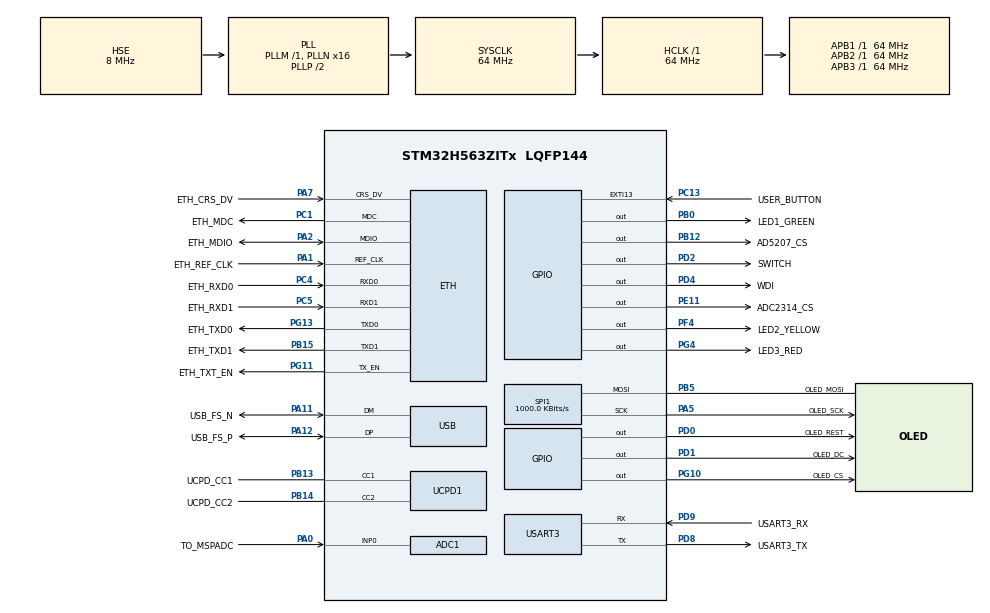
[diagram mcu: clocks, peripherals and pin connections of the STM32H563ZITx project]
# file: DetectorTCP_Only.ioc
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ADC1.Channel-0\#ChannelRegularConversion=ADC_CHANNEL_0
ADC1.ClockPrescaler=ADC_CLOCK_ASYNC_DIV2
ADC1.ContinuousConvMode=DISABLE
ADC1.DMAContinuousRequests=DISABLE
ADC1.DataAlign=ADC_DATAALIGN_RIGHT
ADC1.EOCSelection=ADC_EOC_SINGLE_CONV
ADC1.EnableRegularConversion=ENABLE
ADC1.LowPowerAutoWait=DISABLE
ADC1.MonitoredBy-0\#ChannelRegularConversion=__NULL
ADC1.NbrOfConversionFlag=1
ADC1.OffsetNumber-0\#ChannelRegularConversion=ADC_OFFSET_NONE
ADC1.Overrun=ADC_OVR_DATA_PRESERVED
ADC1.OversamplingMode=DISABLE
ADC1.Rank-0\#ChannelRegularConversion=1
ADC1.Resolution=ADC_RESOLUTION_12B
ADC1.SamplingTime-0\#ChannelRegularConversion=ADC_SAMPLETIME_2CYCLES_5
ADC1.master=1
BOOTPATH.BootPathName=LEGACY
BOOTPATH.UserSelectedBootPath=LEGACY
CORTEX_M33_NS.userName=CORTEX_M33
ETH.MediaInterface=HAL_ETH_RMII_MODE
FLASH.OB_EDATA1_active=true
FLASH.OB_EDATA2_active=true
GPDMA1.DIRECTION_GPDMACH0=DMA_MEMORY_TO_PERIPH
GPDMA1.IPHANDLE_GPDMACH0-SIMPLEREQUEST_GPDMACH0=__NULL
GPDMA1.RECAP_GPDMACH0=DMA_REQUEST_USART3_TX
GPDMA1.REQUEST_GPDMACH0=GPDMA1_REQUEST_USART3_RX
GPDMA1.SRCINC_GPDMACH0=DMA_SINC_INCREMENTED
GPDMA2.CIRCULARMODE_GPDMACH0=ENABLE
GPDMA2.DESTDATAWIDTH_GPDMACH0=DMA_DEST_DATAWIDTH_HALFWORD
GPDMA2.DESTINC_GPDMACH0=DMA_DINC_INCREMENTED
GPDMA2.DIRECTION_GPDMACH0=DMA_PERIPH_TO_MEMORY
GPDMA2.IPHANDLE_GPDMACH0-SIMPLEREQUEST_GPDMACH0=__NULL
GPDMA2.LINKALLOCATEDPORT_CIRCULAR_GPDMACH0=DMA_LINK_ALLOCATED_PORT1
GPDMA2.PRIORITY_LL_CIRCULAR_GPDMACH0=DMA_LOW_PRIORITY_HIGH_WEIGHT
GPDMA2.RECAP_GPDMACH0=DMA_REQUEST_ADC1
GPDMA2.REQUEST_GPDMACH0=GPDMA2_REQUEST_ADC1
GPDMA2.SRCDATAWIDTH_GPDMACH0=DMA_SRC_DATAWIDTH_HALFWORD
GPDMA2.TRANSFERALLOCATEDPORTDEST_GPDMACH0=DMA_DEST_ALLOCATED_PORT1
GPDMA2.TRANSFERALLOCATEDPORTSRC_GPDMACH0=DMA_SRC_ALLOCATED_PORT1
Mcu.Family=STM32H5
Mcu.Name=STM32H563ZITx
Mcu.Package=LQFP144
NETXDUO.ETH_ON=1
NETXDUO.LAN_8742=1
NETXDUO.NX_APP_MEM_POOL_SIZE=30*1024
NETXDUO.NX_APP_PACKET_POOL_SIZE=10
NETXDUO.NX_APP_THREAD_STACK_SIZE=2*1024
NETXDUO.NX_ENABLE_DUAL_PACKET_POOL=true
NETXDUO.NX_ENABLE_INTERFACE_CAPABILITY=true
NETXDUO.NetXDuo_Generate_Init_Code=true
NVIC.ETH_IRQn=true\:0\:0\:false\:false\:true\:false\:true\:true\:true
NVIC.GPDMA1_Channel0_IRQn=true\:0\:0\:false\:false\:true\:false\:false\:true\:true
NVIC.GPDMA2_Channel0_IRQn=true\:0\:0\:false\:false\:true\:true\:false\:true\:true
NVIC.PriorityGroup=NVIC_PRIORITYGROUP_4
NVIC.TIM6_IRQn=true\:15\:0\:false\:false\:true\:false\:false\:true\:true
NVIC.TimeBase=TIM6_IRQn
NVIC.TimeBaseIP=TIM6
NVIC.USART3_IRQn=true\:0\:0\:false\:false\:true\:false\:true\:true\:true
NetXDuo.BSP.number=1
NetXDuo0.BSP.STBoard=false
NetXDuo0.BSP.api=BSP_COMPONENT_DRIVER
NetXDuo0.BSP.component=lan8742
NetXDuo0.BSP.instance=lan8742
NetXDuo0.BSP.name=LAN_Component
NetXDuo0.BSP.semaphore=SEMA_lan8742
NetXDuo0.BSP.solution=lan8742
PA0.GPIO_Label=TO_MSPADC
PA0.Signal=ADCx_INP0
PA1.GPIO_Label=ETH_REF_CLK
PA1.GPIO_Mode=GPIO_MODE_AF_PP
PA1.GPIO_PuPd=GPIO_NOPULL
PA1.GPIO_Speed=GPIO_SPEED_FREQ_LOW
PA1.Mode=RMII
PA1.Signal=ETH_REF_CLK
PA11.GPIO_Label=USB_FS_N
PA11.Mode=Device
PA11.Signal=USB_DM
PA12.GPIO_Label=USB_FS_P
PA12.Mode=Device
PA12.Signal=USB_DP
PA2.GPIO_Label=ETH_MDIO
PA2.GPIO_Mode=GPIO_MODE_AF_PP
PA2.GPIO_PuPd=GPIO_NOPULL
PA2.GPIO_Speed=GPIO_SPEED_FREQ_LOW
PA2.Mode=RMII
PA2.Signal=ETH_MDIO
PA5.GPIO_Label=OLED_SCK
PA5.GPIO_Mode=GPIO_MODE_AF_PP
PA5.GPIO_PuPd=GPIO_NOPULL
PA5.GPIO_Speed=GPIO_SPEED_FREQ_LOW
PA5.Mode=Simplex_Bidirectional_Master
PA5.Signal=SPI1_SCK
PA7.GPIO_Label=ETH_CRS_DV
PA7.GPIO_Mode=GPIO_MODE_AF_PP
PA7.GPIO_PuPd=GPIO_NOPULL
PA7.GPIO_Speed=GPIO_SPEED_FREQ_LOW
PA7.Mode=RMII
PA7.Signal=ETH_CRS_DV
PB0.GPIO_Label=LED1_GREEN
PB0.Signal=GPIO_Output
PB10.GPIO_Label=ADC_CLCK
PB10.Signal=SPI2_SCK
PB12.GPIO_Label=AD5207_CS
PB12.Signal=GPIO_Output
PB13.GPIO_Label=UCPD_CC1
PB13.Mode=Source_AllSignals
PB13.Signal=UCPD1_CC1
PB14.GPIO_Label=UCPD_CC2
PB14.Mode=Source_AllSignals
PB14.Signal=UCPD1_CC2
PB15.GPIO_Label=ETH_TXD1
PB15.GPIO_Mode=GPIO_MODE_AF_PP
PB15.GPIO_PuPd=GPIO_NOPULL
PB15.GPIO_Speed=GPIO_SPEED_FREQ_LOW
PB15.Mode=RMII
PB15.Signal=ETH_TXD1
PB5.GPIO_Label=OLED_MOSI
PB5.GPIO_Mode=GPIO_MODE_AF_PP
PB5.GPIO_PuPd=GPIO_NOPULL
PB5.GPIO_Speed=GPIO_SPEED_FREQ_LOW
PB5.Mode=Simplex_Bidirectional_Master
PB5.Signal=SPI1_MOSI
PC1.GPIO_Label=ETH_MDC
PC1.GPIO_Mode=GPIO_MODE_AF_PP
PC1.GPIO_PuPd=GPIO_NOPULL
PC1.GPIO_Speed=GPIO_SPEED_FREQ_LOW
PC1.Mode=RMII
PC1.Signal=ETH_MDC
PC13.GPIO_Label=USER_BUTTON
PC13.Signal=GPXTI13
PC3.GPIO_Label=AD5207_SDI
PC3.Signal=SPI2_MOSI
PC4.GPIO_Label=ETH_RXD0
PC4.GPIO_Mode=GPIO_MODE_AF_PP
PC4.GPIO_PuPd=GPIO_NOPULL
PC4.GPIO_Speed=GPIO_SPEED_FREQ_LOW
PC4.Mode=RMII
PC4.Signal=ETH_RXD0
PC5.GPIO_Label=ETH_RXD1
PC5.GPIO_Mode=GPIO_MODE_AF_PP
PC5.GPIO_PuPd=GPIO_NOPULL
PC5.GPIO_Speed=GPIO_SPEED_FREQ_LOW
PC5.Mode=RMII
PC5.Signal=ETH_RXD1
PD0.GPIO_Label=OLED_REST
PD0.GPIO_PuPd=GPIO_NOPULL
PD0.PinState=GPIO_PIN_SET
PD0.Signal=GPIO_Output
PD1.GPIO_Label=OLED_DC
PD1.Signal=GPIO_Output
PD2.GPIO_Label=SWITCH
PD2.Signal=GPIO_Output
PD4.GPIO_Label=WDI
PD4.Signal=GPIO_Output
PD8.GPIO_Label=USART3_TX
PD8.Mode=Asynchronous
PD8.Signal=USART3_TX
PD9.GPIO_Label=USART3_RX
PD9.Mode=Asynchronous
PD9.Signal=USART3_RX
PE11.GPIO_Label=ADC2314_CS
PE11.Signal=GPIO_Output
PE12.GPIO_Label=ADC2314_SCK
PE12.Signal=SPI4_SCK
PE13.GPIO_Label=ADC2314_MISO
PE13.Signal=SPI4_MISO
PF4.GPIO_Label=LED2_YELLOW
PF4.Signal=GPIO_Output
PG10.GPIO_Label=OLED_CS
PG10.Signal=GPIO_Output
PG11.GPIO_Label=ETH_TXT_EN
PG11.GPIO_Mode=GPIO_MODE_AF_PP
PG11.GPIO_PuPd=GPIO_NOPULL
PG11.GPIO_Speed=GPIO_SPEED_FREQ_LOW
PG11.Mode=RMII
PG11.Signal=ETH_TX_EN
PG13.GPIO_Label=ETH_TXD0
PG13.GPIO_Mode=GPIO_MODE_AF_PP
PG13.GPIO_PuPd=GPIO_NOPULL
PG13.GPIO_Speed=GPIO_SPEED_FREQ_LOW
PG13.Mode=RMII
PG13.Signal=ETH_TXD0
PG4.GPIO_Label=LED3_RED
PG4.Signal=GPIO_Output
PH0-OSC_IN(PH0).Mode=HSE-External-Clock-Source
PH0-OSC_IN(PH0).Signal=RCC_OSC_IN
ProjectManager.HeapSize=0x200
ProjectManager.StackSize=0x400
ProjectManager.TargetToolchain=STM32CubeIDE
RCC.ADCFreq_Value=64000000
RCC.AHBFreq_Value=64000000
RCC.APB1Freq_Value=64000000
RCC.APB1TimFreq_Value=64000000
RCC.APB2Freq_Value=64000000
RCC.APB2TimFreq_Value=64000000
RCC.APB3Freq_Value=64000000
RCC.CSI_VALUE=4000000
RCC.CortexFreq_Value=64000000
RCC.EPOD_VALUE=8000000
RCC.HCLKFreq_Value=64000000
RCC.HSE_VALUE=8000000
RCC.HSI48_VALUE=48000000
RCC.HSIDiv=RCC_HSI_DIV1
RCC.HSI_VALUE=64000000
RCC.LSE_VALUE=32768
RCC.LSIRC_VALUE=32000
RCC.PLL2FRACN=0
RCC.PLL3FRACN=0
RCC.PLLFRACN=0
RCC.PLLN=16
RCC.PLLSourceVirtual=RCC_PLL1_SOURCE_HSE
RCC.PWR_Regulator_Voltage_Scale=PWR_REGULATOR_VOLTAGE_SCALE0
RCC.SYSCLKFreq_VALUE=64000000
RCC.SYSCLKSource=RCC_SYSCLKSOURCE_PLLCLK
RCC.USBFreq_Value=48000000
RCC.VCOOutputFreq_Value=128000000
RCC.rccPrivilegeNSecure=RCC_NSEC_PRIV
SH.ADCx_INP0.0=ADC1_INP0,IN0-Single-Ended
SPI1.BaudRatePrescaler=SPI_BAUDRATEPRESCALER_64
SPI1.CLKPolarity=SPI_POLARITY_LOW
SPI1.CalculateBaudRate=1000.0 KBits/s
SPI1.DataSize=SPI_DATASIZE_8BIT
SPI1.Direction=SPI_DIRECTION_1LINE
SPI1.IOSwap=SPI_IO_SWAP_DISABLE
SPI1.MasterInterDataIdleness=SPI_MASTER_INTERDATA_IDLENESS_00CYCLE
SPI1.MasterKeepIOState=SPI_MASTER_KEEP_IO_STATE_ENABLE
SPI1.MasterReceiverAutoSusp=SPI_MASTER_RX_AUTOSUSP_ENABLE
SPI1.MasterSSIdleness=SPI_MASTER_SS_IDLENESS_00CYCLE
SPI1.Mode=SPI_MODE_MASTER
SPI1.NSSPolarity=SPI_NSS_POLARITY_HIGH
SPI1.ReadyPolarity=SPI_RDY_POLARITY_LOW
SPI1.VirtualType=VM_MASTER
TIM13.AutoReloadPreload=TIM_AUTORELOAD_PRELOAD_ENABLE
TIM13.ClockDivision=TIM_CLOCKDIVISION_DIV2
TIM13.PeriodNoDither=525
USART3.DataInvertParam=ADVFEATURE_DATAINV_DISABLE
USART3.MSBFirstParam=ADVFEATURE_MSBFIRST_DISABLE
USART3.OverSampling=UART_OVERSAMPLING_16
USART3.RxPinLevelInvertParam=ADVFEATURE_RXINV_DISABLE
USART3.VirtualMode=VM_ASYNC
USART3.WordLength=WORDLENGTH_8B
USB.VirtualMode=Device_Only
VP_BOOTPATH_VS_BOOTPATH.Mode=BP_Activate
VP_FLASH_SIG_Activate_FlashIP.Mode=Activate_FlashIP
VP_GPDMA1_VS_GPDMACH0.Mode=SIMPLEREQUEST_GPDMACH0
VP_GPDMA2_VS_GPDMACH0.Mode=SIMPLEREQUEST_GPDMACH0
VP_ICACHE_VS_ICACHE.Mode=DefaultMode
VP_MEMORYMAP_VS_MEMORYMAP.Mode=CurAppReg
VP_NETXDUO_VS_AddonsOoDHCP.Mode=Addons_DHCP_Client
VP_NETXDUO_VS_EthernetOoPhyOoInterface.Mode=LAN8742_Phy_Interface
VP_NETXDUO_VS_NXOoCore.Mode=NX_Core
VP_NETXDUO_VS_NetworkOoInterface.Mode=Ethernet_Interface
VP_PWR_VS_DBSignals.Mode=DisableDeadBatterySignals
VP_PWR_VS_LPOM.Mode=PowerOptimisation
VP_PWR_VS_SECSignals.Mode=Security/Privilege
VP_SYS_VS_tim6.Mode=TIM6
VP_THREADX_VS_RTOSJjThreadXJjCoreJjDefault.Mode=Core_Default
VP_TIM13_VS_ClockSourceINT.Mode=Enable_Timer
board=NUCLEO-H563ZI

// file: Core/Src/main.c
/* USER CODE BEGIN Header */
/**
  ******************************************************************************
  * @file           : main.c
  * @brief          : Main program body
  ******************************************************************************
  * @attention
  *
  * Copyright (c) 2024 STMicroelectronics.
  * All rights reserved.
  *
  * This software is licensed under terms that can be found in the LICENSE file
  * in the root directory of this software component.
  * If no LICENSE file comes with this software, it is provided AS-IS.
  *
  ******************************************************************************
  */
/* USER CODE END Header */
#include "app_threadx.h"
#include "main.h"
#include "string.h"

/* USER CODE BEGIN Includes */
#include <stdio.h>
#include "../vs_info.h"
#include "../global.h"
#include "../hal_src/HAL.h"
#include "../ssd1306_src/ssd1306.h"
#include "../ssd1306_src/ssd1306_tests.h"
#include "../ssd1306_src/ssd1306_conf.h"
/* USER CODE END Includes */

ETH_TxPacketConfig TxConfig;
ETH_DMADescTypeDef  DMARxDscrTab[ETH_RX_DESC_CNT]; /* Ethernet Rx DMA Descriptors */
ETH_DMADescTypeDef  DMATxDscrTab[ETH_TX_DESC_CNT]; /* Ethernet Tx DMA Descriptors */

ADC_HandleTypeDef hadc1;
DMA_NodeTypeDef Node_GPDMA2_Channel0;
DMA_QListTypeDef List_GPDMA2_Channel0;
DMA_HandleTypeDef handle_GPDMA2_Channel0;

ETH_HandleTypeDef heth;

SPI_HandleTypeDef hspi1;

TIM_HandleTypeDef htim13;

UART_HandleTypeDef huart3;
DMA_HandleTypeDef handle_GPDMA1_Channel0;

PCD_HandleTypeDef hpcd_USB_DRD_FS;

void SystemClock_Config(void);
static void MX_GPIO_Init(void);
static void MX_GPDMA1_Init(void);
static void MX_GPDMA2_Init(void);
static void MX_ICACHE_Init(void);
static void MX_USART3_UART_Init(void);
static void MX_UCPD1_Init(void);
static void MX_USB_PCD_Init(void);
static void MX_ADC1_Init(void);
static void MX_SPI1_Init(void);
static void MX_ETH_Init(void);
static void MX_TIM13_Init(void);
static void MX_FLASH_Init(void);

int main(void)
{

  /* MCU Configuration--------------------------------------------------------*/

  /* Reset of all peripherals, Initializes the Flash interface and the Systick. */
  HAL_Init();

  /* Configure the system clock */
  SystemClock_Config();

  /* Initialize all configured peripherals */
  MX_GPIO_Init();
  MX_GPDMA1_Init();
  MX_GPDMA2_Init();
  MX_ICACHE_Init();
  MX_USART3_UART_Init();
  MX_UCPD1_Init();
  MX_USB_PCD_Init();
  MX_ADC1_Init();
  MX_SPI1_Init();
  MX_ETH_Init();
  MX_TIM13_Init();
  MX_FLASH_Init();
  /* USER CODE BEGIN 2 */
  Output("Patates!$");
  /* USER CODE END 2 */

  MX_ThreadX_Init();

  /* We should never get here as control is now taken by the scheduler */
  /* Infinite loop */
  while (1)
  {

  }
}

void SystemClock_Config(void)
{
  RCC_OscInitTypeDef RCC_OscInitStruct = {0};
  RCC_ClkInitTypeDef RCC_ClkInitStruct = {0};

  /** Configure the main internal regulator output voltage
  */
  __HAL_PWR_VOLTAGESCALING_CONFIG(PWR_REGULATOR_VOLTAGE_SCALE0);

  while(!__HAL_PWR_GET_FLAG(PWR_FLAG_VOSRDY)) {}

  /** Initializes the RCC Oscillators according to the specified parameters
  * in the RCC_OscInitTypeDef structure.
  */
  RCC_OscInitStruct.OscillatorType = RCC_OSCILLATORTYPE_HSI48|RCC_OSCILLATORTYPE_HSI
                              |RCC_OSCILLATORTYPE_HSE;
  RCC_OscInitStruct.HSEState = RCC_HSE_BYPASS;
  RCC_OscInitStruct.HSIState = RCC_HSI_ON;
  RCC_OscInitStruct.HSIDiv = RCC_HSI_DIV1;
  RCC_OscInitStruct.HSICalibrationValue = RCC_HSICALIBRATION_DEFAULT;
  RCC_OscInitStruct.HSI48State = RCC_HSI48_ON;
  RCC_OscInitStruct.PLL.PLLState = RCC_PLL_ON;
  RCC_OscInitStruct.PLL.PLLSource = RCC_PLL1_SOURCE_HSE;
  RCC_OscInitStruct.PLL.PLLM = 1;
  RCC_OscInitStruct.PLL.PLLN = 16;
  RCC_OscInitStruct.PLL.PLLP = 2;
  RCC_OscInitStruct.PLL.PLLQ = 2;
  RCC_OscInitStruct.PLL.PLLR = 2;
  RCC_OscInitStruct.PLL.PLLRGE = RCC_PLL1_VCIRANGE_3;
  RCC_OscInitStruct.PLL.PLLVCOSEL = RCC_PLL1_VCORANGE_WIDE;
  RCC_OscInitStruct.PLL.PLLFRACN = 0;
  if (HAL_RCC_OscConfig(&RCC_OscInitStruct) != HAL_OK)
  {
    Error_Handler();
  }

  /** Initializes the CPU, AHB and APB buses clocks
  */
  RCC_ClkInitStruct.ClockType = RCC_CLOCKTYPE_HCLK|RCC_CLOCKTYPE_SYSCLK
                              |RCC_CLOCKTYPE_PCLK1|RCC_CLOCKTYPE_PCLK2
                              |RCC_CLOCKTYPE_PCLK3;
  RCC_ClkInitStruct.SYSCLKSource = RCC_SYSCLKSOURCE_PLLCLK;
  RCC_ClkInitStruct.AHBCLKDivider = RCC_SYSCLK_DIV1;
  RCC_ClkInitStruct.APB1CLKDivider = RCC_HCLK_DIV1;
  RCC_ClkInitStruct.APB2CLKDivider = RCC_HCLK_DIV1;
  RCC_ClkInitStruct.APB3CLKDivider = RCC_HCLK_DIV1;

  if (HAL_RCC_ClockConfig(&RCC_ClkInitStruct, FLASH_LATENCY_1) != HAL_OK)
  {
    Error_Handler();
  }
  HAL_RCC_ConfigAttributes(RCC_ALL, RCC_NSEC_PRIV);
}

static void MX_ADC1_Init(void)
{

  ADC_ChannelConfTypeDef sConfig = {0};

  /** Common config
  */
  hadc1.Instance = ADC1;
  hadc1.Init.ClockPrescaler = ADC_CLOCK_ASYNC_DIV2;
  hadc1.Init.Resolution = ADC_RESOLUTION_12B;
  hadc1.Init.DataAlign = ADC_DATAALIGN_RIGHT;
  hadc1.Init.ScanConvMode = ADC_SCAN_DISABLE;
  hadc1.Init.EOCSelection = ADC_EOC_SINGLE_CONV;
  hadc1.Init.LowPowerAutoWait = DISABLE;
  hadc1.Init.ContinuousConvMode = DISABLE;
  hadc1.Init.NbrOfConversion = 1;
  hadc1.Init.DiscontinuousConvMode = DISABLE;
  hadc1.Init.ExternalTrigConv = ADC_SOFTWARE_START;
  hadc1.Init.ExternalTrigConvEdge = ADC_EXTERNALTRIGCONVEDGE_NONE;
  hadc1.Init.DMAContinuousRequests = DISABLE;
  hadc1.Init.SamplingMode = ADC_SAMPLING_MODE_NORMAL;
  hadc1.Init.Overrun = ADC_OVR_DATA_PRESERVED;
  hadc1.Init.OversamplingMode = DISABLE;
  if (HAL_ADC_Init(&hadc1) != HAL_OK)
  {
    Error_Handler();
  }

  /** Configure Regular Channel
  */
  sConfig.Channel = ADC_CHANNEL_0;
  sConfig.Rank = ADC_REGULAR_RANK_1;
  sConfig.SamplingTime = ADC_SAMPLETIME_2CYCLES_5;
  sConfig.SingleDiff = ADC_SINGLE_ENDED;
  sConfig.OffsetNumber = ADC_OFFSET_NONE;
  sConfig.Offset = 0;
  if (HAL_ADC_ConfigChannel(&hadc1, &sConfig) != HAL_OK)
  {
    Error_Handler();
  }

}

static void MX_ETH_Init(void)
{

   static uint8_t MACAddr[6];

  heth.Instance = ETH;
  MACAddr[0] = 0x00;
  MACAddr[1] = 0x80;
  MACAddr[2] = 0xE1;
  MACAddr[3] = 0x00;
  MACAddr[4] = 0x00;
  MACAddr[5] = 0x00;
  heth.Init.MACAddr = &MACAddr[0];
  heth.Init.MediaInterface = HAL_ETH_RMII_MODE;
  heth.Init.TxDesc = DMATxDscrTab;
  heth.Init.RxDesc = DMARxDscrTab;
  heth.Init.RxBuffLen = 1524;

  if (HAL_ETH_Init(&heth) != HAL_OK)
  {
    Error_Handler();
  }

  memset(&TxConfig, 0 , sizeof(ETH_TxPacketConfig));
  TxConfig.Attributes = ETH_TX_PACKETS_FEATURES_CSUM | ETH_TX_PACKETS_FEATURES_CRCPAD;
  TxConfig.ChecksumCtrl = ETH_CHECKSUM_IPHDR_PAYLOAD_INSERT_PHDR_CALC;
  TxConfig.CRCPadCtrl = ETH_CRC_PAD_INSERT;

}

static void MX_FLASH_Init(void)
{

  FLASH_OBProgramInitTypeDef pOBInit = {0};

  if (HAL_FLASH_Unlock() != HAL_OK)
  {
    Error_Handler();
  }

  /* Option Bytes settings */

  if (HAL_FLASH_OB_Unlock() != HAL_OK)
  {
    Error_Handler();
  }
  pOBInit.OptionType = OPTIONBYTE_EDATA;
  pOBInit.Banks = FLASH_BANK_BOTH;
  pOBInit.EDATASize = 0;
  if (HAL_FLASHEx_OBProgram(&pOBInit) != HAL_OK)
  {
    Error_Handler();
  }
  if (HAL_FLASH_OB_Lock() != HAL_OK)
  {
    Error_Handler();
  }
  if (HAL_FLASH_Lock() != HAL_OK)
  {
    Error_Handler();
  }

  /* Launch Option Bytes Loading */
  /*HAL_FLASH_OB_Launch(); */

}

static void MX_GPDMA1_Init(void)
{

  /* Peripheral clock enable */
  __HAL_RCC_GPDMA1_CLK_ENABLE();

  /* GPDMA1 interrupt Init */
    HAL_NVIC_SetPriority(GPDMA1_Channel0_IRQn, 0, 0);
    HAL_NVIC_EnableIRQ(GPDMA1_Channel0_IRQn);

}

static void MX_GPDMA2_Init(void)
{

  /* Peripheral clock enable */
  __HAL_RCC_GPDMA2_CLK_ENABLE();

  /* GPDMA2 interrupt Init */
    HAL_NVIC_SetPriority(GPDMA2_Channel0_IRQn, 0, 0);
    HAL_NVIC_EnableIRQ(GPDMA2_Channel0_IRQn);

}

static void MX_ICACHE_Init(void)
{

  /** Enable instruction cache (default 2-ways set associative cache)
  */
  if (HAL_ICACHE_Enable() != HAL_OK)
  {
    Error_Handler();
  }

}

static void MX_SPI1_Init(void)
{

  /* SPI1 parameter configuration*/
  hspi1.Instance = SPI1;
  hspi1.Init.Mode = SPI_MODE_MASTER;
  hspi1.Init.Direction = SPI_DIRECTION_1LINE;
  hspi1.Init.DataSize = SPI_DATASIZE_8BIT;
  hspi1.Init.CLKPolarity = SPI_POLARITY_LOW;
  hspi1.Init.CLKPhase = SPI_PHASE_1EDGE;
  hspi1.Init.NSS = SPI_NSS_SOFT;
  hspi1.Init.BaudRatePrescaler = SPI_BAUDRATEPRESCALER_64;
  hspi1.Init.FirstBit = SPI_FIRSTBIT_MSB;
  hspi1.Init.TIMode = SPI_TIMODE_DISABLE;
  hspi1.Init.CRCCalculation = SPI_CRCCALCULATION_DISABLE;
  hspi1.Init.CRCPolynomial = 0x7;
  hspi1.Init.NSSPMode = SPI_NSS_PULSE_ENABLE;
  hspi1.Init.NSSPolarity = SPI_NSS_POLARITY_HIGH;
  hspi1.Init.FifoThreshold = SPI_FIFO_THRESHOLD_01DATA;
  hspi1.Init.MasterSSIdleness = SPI_MASTER_SS_IDLENESS_00CYCLE;
  hspi1.Init.MasterInterDataIdleness = SPI_MASTER_INTERDATA_IDLENESS_00CYCLE;
  hspi1.Init.MasterReceiverAutoSusp = SPI_MASTER_RX_AUTOSUSP_ENABLE;
  hspi1.Init.MasterKeepIOState = SPI_MASTER_KEEP_IO_STATE_ENABLE;
  hspi1.Init.IOSwap = SPI_IO_SWAP_DISABLE;
  hspi1.Init.ReadyMasterManagement = SPI_RDY_MASTER_MANAGEMENT_INTERNALLY;
  hspi1.Init.ReadyPolarity = SPI_RDY_POLARITY_LOW;
  if (HAL_SPI_Init(&hspi1) != HAL_OK)
  {
    Error_Handler();
  }

}

static void MX_TIM13_Init(void)
{

  htim13.Instance = TIM13;
  htim13.Init.Prescaler = 0;
  htim13.Init.CounterMode = TIM_COUNTERMODE_UP;
  htim13.Init.Period = 525;
  htim13.Init.ClockDivision = TIM_CLOCKDIVISION_DIV2;
  htim13.Init.AutoReloadPreload = TIM_AUTORELOAD_PRELOAD_ENABLE;
  if (HAL_TIM_Base_Init(&htim13) != HAL_OK)
  {
    Error_Handler();
  }

}

static void MX_UCPD1_Init(void)
{

  LL_GPIO_InitTypeDef GPIO_InitStruct = {0};

  /* Peripheral clock enable */
  LL_APB1_GRP2_EnableClock(LL_APB1_GRP2_PERIPH_UCPD1);

  LL_AHB2_GRP1_EnableClock(LL_AHB2_GRP1_PERIPH_GPIOB);
  /**UCPD1 GPIO Configuration
  PB13   ------> UCPD1_CC1
  PB14   ------> UCPD1_CC2
  */
  GPIO_InitStruct.Pin = LL_GPIO_PIN_13|LL_GPIO_PIN_14;
  GPIO_InitStruct.Mode = LL_GPIO_MODE_ANALOG;
  GPIO_InitStruct.Pull = LL_GPIO_PULL_NO;
  LL_GPIO_Init(GPIOB, &GPIO_InitStruct);

}

static void MX_USART3_UART_Init(void)
{

  huart3.Instance = USART3;
  huart3.Init.BaudRate = 115200;
  huart3.Init.WordLength = UART_WORDLENGTH_8B;
  huart3.Init.StopBits = UART_STOPBITS_1;
  huart3.Init.Parity = UART_PARITY_NONE;
  huart3.Init.Mode = UART_MODE_TX_RX;
  huart3.Init.HwFlowCtl = UART_HWCONTROL_NONE;
  huart3.Init.OverSampling = UART_OVERSAMPLING_16;
  huart3.Init.OneBitSampling = UART_ONE_BIT_SAMPLE_DISABLE;
  huart3.Init.ClockPrescaler = UART_PRESCALER_DIV1;
  huart3.AdvancedInit.AdvFeatureInit = UART_ADVFEATURE_NO_INIT;
  if (HAL_UART_Init(&huart3) != HAL_OK)
  {
    Error_Handler();
  }
  if (HAL_UARTEx_SetTxFifoThreshold(&huart3, UART_TXFIFO_THRESHOLD_1_8) != HAL_OK)
  {
    Error_Handler();
  }
  if (HAL_UARTEx_SetRxFifoThreshold(&huart3, UART_RXFIFO_THRESHOLD_1_8) != HAL_OK)
  {
    Error_Handler();
  }
  if (HAL_UARTEx_DisableFifoMode(&huart3) != HAL_OK)
  {
    Error_Handler();
  }

}

static void MX_USB_PCD_Init(void)
{

  hpcd_USB_DRD_FS.Instance = USB_DRD_FS;
  hpcd_USB_DRD_FS.Init.dev_endpoints = 8;
  hpcd_USB_DRD_FS.Init.speed = USBD_FS_SPEED;
  hpcd_USB_DRD_FS.Init.phy_itface = PCD_PHY_EMBEDDED;
  hpcd_USB_DRD_FS.Init.Sof_enable = DISABLE;
  hpcd_USB_DRD_FS.Init.low_power_enable = DISABLE;
  hpcd_USB_DRD_FS.Init.lpm_enable = DISABLE;
  hpcd_USB_DRD_FS.Init.battery_charging_enable = DISABLE;
  hpcd_USB_DRD_FS.Init.vbus_sensing_enable = DISABLE;
  hpcd_USB_DRD_FS.Init.bulk_doublebuffer_enable = DISABLE;
  hpcd_USB_DRD_FS.Init.iso_singlebuffer_enable = DISABLE;
  if (HAL_PCD_Init(&hpcd_USB_DRD_FS) != HAL_OK)
  {
    Error_Handler();
  }

}

static void MX_GPIO_Init(void)
{
  GPIO_InitTypeDef GPIO_InitStruct = {0};

  /* GPIO Ports Clock Enable */
  __HAL_RCC_GPIOC_CLK_ENABLE();
  __HAL_RCC_GPIOF_CLK_ENABLE();
  __HAL_RCC_GPIOH_CLK_ENABLE();
  __HAL_RCC_GPIOA_CLK_ENABLE();
  __HAL_RCC_GPIOB_CLK_ENABLE();
  __HAL_RCC_GPIOE_CLK_ENABLE();
  __HAL_RCC_GPIOD_CLK_ENABLE();
  __HAL_RCC_GPIOG_CLK_ENABLE();

  /*Configure GPIO pin Output Level */
  HAL_GPIO_WritePin(LED2_YELLOW_GPIO_Port, LED2_YELLOW_Pin, GPIO_PIN_RESET);

  /*Configure GPIO pin Output Level */
  HAL_GPIO_WritePin(GPIOB, LED1_GREEN_Pin|AD5207_CS_Pin, GPIO_PIN_RESET);

  /*Configure GPIO pin Output Level */
  HAL_GPIO_WritePin(ADC2314_CS_GPIO_Port, ADC2314_CS_Pin, GPIO_PIN_RESET);

  /*Configure GPIO pin Output Level */
  HAL_GPIO_WritePin(GPIOG, LED3_RED_Pin|OLED_CS_Pin, GPIO_PIN_RESET);

  /*Configure GPIO pin Output Level */
  HAL_GPIO_WritePin(OLED_REST_GPIO_Port, OLED_REST_Pin, GPIO_PIN_SET);

  /*Configure GPIO pin Output Level */
  HAL_GPIO_WritePin(GPIOD, OLED_DC_Pin|SWITCH_Pin|WDI_Pin, GPIO_PIN_RESET);

  /*Configure GPIO pin : USER_BUTTON_Pin */
  GPIO_InitStruct.Pin = USER_BUTTON_Pin;
  GPIO_InitStruct.Mode = GPIO_MODE_IT_RISING;
  GPIO_InitStruct.Pull = GPIO_NOPULL;
  HAL_GPIO_Init(USER_BUTTON_GPIO_Port, &GPIO_InitStruct);

  /*Configure GPIO pin : LED2_YELLOW_Pin */
  GPIO_InitStruct.Pin = LED2_YELLOW_Pin;
  GPIO_InitStruct.Mode = GPIO_MODE_OUTPUT_PP;
  GPIO_InitStruct.Pull = GPIO_NOPULL;
  GPIO_InitStruct.Speed = GPIO_SPEED_FREQ_LOW;
  HAL_GPIO_Init(LED2_YELLOW_GPIO_Port, &GPIO_InitStruct);

  /*Configure GPIO pin : AD5207_SDI_Pin */
  GPIO_InitStruct.Pin = AD5207_SDI_Pin;
  GPIO_InitStruct.Mode = GPIO_MODE_AF_PP;
  GPIO_InitStruct.Pull = GPIO_NOPULL;
  GPIO_InitStruct.Speed = GPIO_SPEED_FREQ_LOW;
  GPIO_InitStruct.Alternate = GPIO_AF5_SPI2;
  HAL_GPIO_Init(AD5207_SDI_GPIO_Port, &GPIO_InitStruct);

  /*Configure GPIO pins : LED1_GREEN_Pin AD5207_CS_Pin */
  GPIO_InitStruct.Pin = LED1_GREEN_Pin|AD5207_CS_Pin;
  GPIO_InitStruct.Mode = GPIO_MODE_OUTPUT_PP;
  GPIO_InitStruct.Pull = GPIO_NOPULL;
  GPIO_InitStruct.Speed = GPIO_SPEED_FREQ_LOW;
  HAL_GPIO_Init(GPIOB, &GPIO_InitStruct);

  /*Configure GPIO pin : ADC2314_CS_Pin */
  GPIO_InitStruct.Pin = ADC2314_CS_Pin;
  GPIO_InitStruct.Mode = GPIO_MODE_OUTPUT_PP;
  GPIO_InitStruct.Pull = GPIO_NOPULL;
  GPIO_InitStruct.Speed = GPIO_SPEED_FREQ_LOW;
  HAL_GPIO_Init(ADC2314_CS_GPIO_Port, &GPIO_InitStruct);

  /*Configure GPIO pins : ADC2314_SCK_Pin ADC2314_MISO_Pin */
  GPIO_InitStruct.Pin = ADC2314_SCK_Pin|ADC2314_MISO_Pin;
  GPIO_InitStruct.Mode = GPIO_MODE_AF_PP;
  GPIO_InitStruct.Pull = GPIO_NOPULL;
  GPIO_InitStruct.Speed = GPIO_SPEED_FREQ_LOW;
  GPIO_InitStruct.Alternate = GPIO_AF5_SPI4;
  HAL_GPIO_Init(GPIOE, &GPIO_InitStruct);

  /*Configure GPIO pin : ADC_CLCK_Pin */
  GPIO_InitStruct.Pin = ADC_CLCK_Pin;
  GPIO_InitStruct.Mode = GPIO_MODE_AF_PP;
  GPIO_InitStruct.Pull = GPIO_NOPULL;
  GPIO_InitStruct.Speed = GPIO_SPEED_FREQ_LOW;
  GPIO_InitStruct.Alternate = GPIO_AF5_SPI2;
  HAL_GPIO_Init(ADC_CLCK_GPIO_Port, &GPIO_InitStruct);

  /*Configure GPIO pins : LED3_RED_Pin OLED_CS_Pin */
  GPIO_InitStruct.Pin = LED3_RED_Pin|OLED_CS_Pin;
  GPIO_InitStruct.Mode = GPIO_MODE_OUTPUT_PP;
  GPIO_InitStruct.Pull = GPIO_NOPULL;
  GPIO_InitStruct.Speed = GPIO_SPEED_FREQ_LOW;
  HAL_GPIO_Init(GPIOG, &GPIO_InitStruct);

  /*Configure GPIO pins : OLED_REST_Pin OLED_DC_Pin SWITCH_Pin WDI_Pin */
  GPIO_InitStruct.Pin = OLED_REST_Pin|OLED_DC_Pin|SWITCH_Pin|WDI_Pin;
  GPIO_InitStruct.Mode = GPIO_MODE_OUTPUT_PP;
  GPIO_InitStruct.Pull = GPIO_NOPULL;
  GPIO_InitStruct.Speed = GPIO_SPEED_FREQ_LOW;
  HAL_GPIO_Init(GPIOD, &GPIO_InitStruct);

}

void HAL_TIM_PeriodElapsedCallback(TIM_HandleTypeDef *htim)
{
  if (htim->Instance == TIM6) {
    HAL_IncTick();
  }
}

void Error_Handler(void)
{
  __disable_irq();
  while (1)
  {
  }
}
